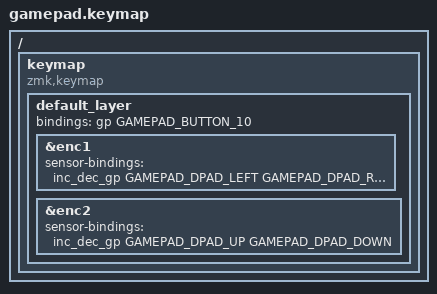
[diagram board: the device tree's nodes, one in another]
#include <behaviors.dtsi>
#include <dt-bindings/zmk/keys.h>

/ {
    keymap {
        compatible = "zmk,keymap";

        default_layer {
            bindings = <
                &gp GAMEPAD_BUTTON_1  &gp GAMEPAD_BUTTON_2  // Ряды 1, столбцы 1-2
                &gp GAMEPAD_BUTTON_3  &gp GAMEPAD_BUTTON_4  // Ряд 2
                &gp GAMEPAD_BUTTON_5  &gp GAMEPAD_BUTTON_6  // Ряд 3
                &gp GAMEPAD_BUTTON_7  &gp GAMEPAD_BUTTON_8  // Ряд 4
            >;

            // Кнопки энкодеров
            bindings = <&gp GAMEPAD_BUTTON_9>;  // Кнопка энкодера 1 (P0.22)
            bindings = <&gp GAMEPAD_BUTTON_10>; // Кнопка энкодера 2 (P1.04)

            // Энкодеры: Кастомные действия (не volume, например, DPAD)
            &enc1 {
                sensor-bindings = <&inc_dec_gp GAMEPAD_DPAD_LEFT GAMEPAD_DPAD_RIGHT>;
            };
            &enc2 {
                sensor-bindings = <&inc_dec_gp GAMEPAD_DPAD_UP GAMEPAD_DPAD_DOWN>;
            };
        };
    };
};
